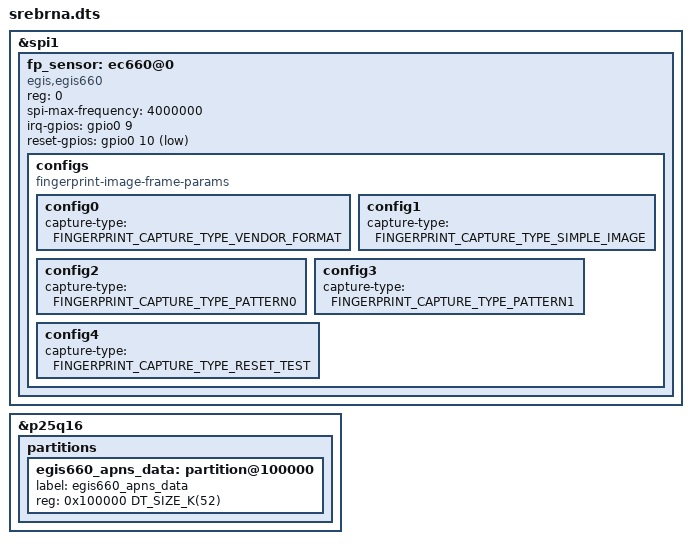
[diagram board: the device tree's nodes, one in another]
/* Copyright 2026 The ChromiumOS Authors.
 * Use of this source code is governed by a BSD-style license that can be
 * found in the LICENSE file.
 */

#include "common.dtsi"

#define EGIS660_COMMON_IMAGE_PROPS \
	width = <96>; \
	height = <100>; \
	bits-per-pixel = <8>; \
	frame-size = <9980>; \
	image-data-offset-bytes = <172>; \
	v4l2-pixel-format = "V4L2_PIX_FMT_GREY";

&spi1 {
	fp_sensor: ec660@0 {
		compatible = "egis,egis660";
		reg = <0>;
		spi-max-frequency = <4000000>;

		configs {
			compatible = "fingerprint-image-frame-params";
			config0 {
				EGIS660_COMMON_IMAGE_PROPS
				capture-type = "FINGERPRINT_CAPTURE_TYPE_VENDOR_FORMAT";
			};
			config1 {
				EGIS660_COMMON_IMAGE_PROPS
				capture-type = "FINGERPRINT_CAPTURE_TYPE_SIMPLE_IMAGE";
			};
			config2 {
				EGIS660_COMMON_IMAGE_PROPS
				capture-type = "FINGERPRINT_CAPTURE_TYPE_PATTERN0";
			};
			config3 {
				EGIS660_COMMON_IMAGE_PROPS
				capture-type = "FINGERPRINT_CAPTURE_TYPE_PATTERN1";
			};
			config4 {
				EGIS660_COMMON_IMAGE_PROPS
				capture-type = "FINGERPRINT_CAPTURE_TYPE_RESET_TEST";
			};
		};

		irq-gpios = <&gpio0 9 GPIO_ACTIVE_HIGH>;
		reset-gpios = <&gpio0 10 GPIO_ACTIVE_LOW>;
	};
};

&p25q16 {
	partitions {
		egis660_apns_data: partition@100000 {
			label = "egis660_apns_data";
			reg = <0x100000 DT_SIZE_K(52)>;
		};
	};
};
